# f28p65x_mindb_xbar_regs register map
Vendor: Texas Instruments
Peripheral module from a debugger description file (folder C2000).
Address unit: 16 bits
Registers are 16-bit, read-write, no defined reset value unless marked. A register's access mark holds for its fields unless they carry their own. Offsets are as the file gives them; lines under a group give offsets from that group; [hi:lo] are bit positions; {n}, {i} and the like mark numbered series; 'fields as' and 'values as' point back to an identical list; <NAME> marks a mode.

## MINDB_XBAR_REGS — MINDB XBAR Registers
0x00 MDL1SELECT — MDL1SELECT Input Select Register
  [15:0] SELECT — Select INPUT for MDL1 signal
0x01 MDL2SELECT — MDL2SELECT Input Select Register
  [15:0] SELECT — Select INPUT for MDL2 signal
0x02 MDL3SELECT — MDL3SELECT Input Select Register
  [15:0] SELECT — Select INPUT for MDL3 signal
0x03 MDL4SELECT — MDL4SELECT Input Select Register
  [15:0] SELECT — Select INPUT for MDL4 signal
0x04 MDL5SELECT — MDL5SELECT Input Select Register
  [15:0] SELECT — Select INPUT for MDL5 signal
0x05 MDL6SELECT — MDL6SELECT Input Select Register
  [15:0] SELECT — Select INPUT for MDL6 signal
0x06 MDL7SELECT — MDL7SELECT Input Select Register
  [15:0] SELECT — Select INPUT for MDL7 signal
0x07 MDL8SELECT — MDL8SELECT Input Select Register
  [15:0] SELECT — Select INPUT for MDL8 signal
0x08 MDL9SELECT — MDL9SELECT Input Select Register
  [15:0] SELECT — Select INPUT for MDL9 signal
0x09 MDL10SELECT — MDL10SELECT Input Select Register
  [15:0] SELECT — Select INPUT for MDL10 signal
0x0A MDL11SELECT — MDL11SELECT Input Select Register
  [15:0] SELECT — Select INPUT for MDL11 signal
0x0B MDL12SELECT — MDL12SELECT Input Select Register
  [15:0] SELECT — Select INPUT for MDL12 signal
0x0C MDL13SELECT — MDL13SELECT Input Select Register
  [15:0] SELECT — Select INPUT for MDL13 signal
0x0D MDL14SELECT — MDL14SELECT Input Select Register
  [15:0] SELECT — Select INPUT for MDL14 signal
0x0E MDL15SELECT — MDL15SELECT Input Select Register
  [15:0] SELECT — Select INPUT for MDL15 signal
0x0F MDL16SELECT — MDL16SELECT Input Select Register
  [15:0] SELECT — Select INPUT for MDL16 signal
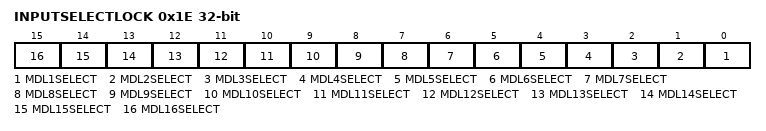
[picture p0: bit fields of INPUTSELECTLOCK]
0x1E INPUTSELECTLOCK 32-bit
  [n-1] MDL{n}SELECT (n=1..16) — Lock bit for MDL{n}SELECT Register
